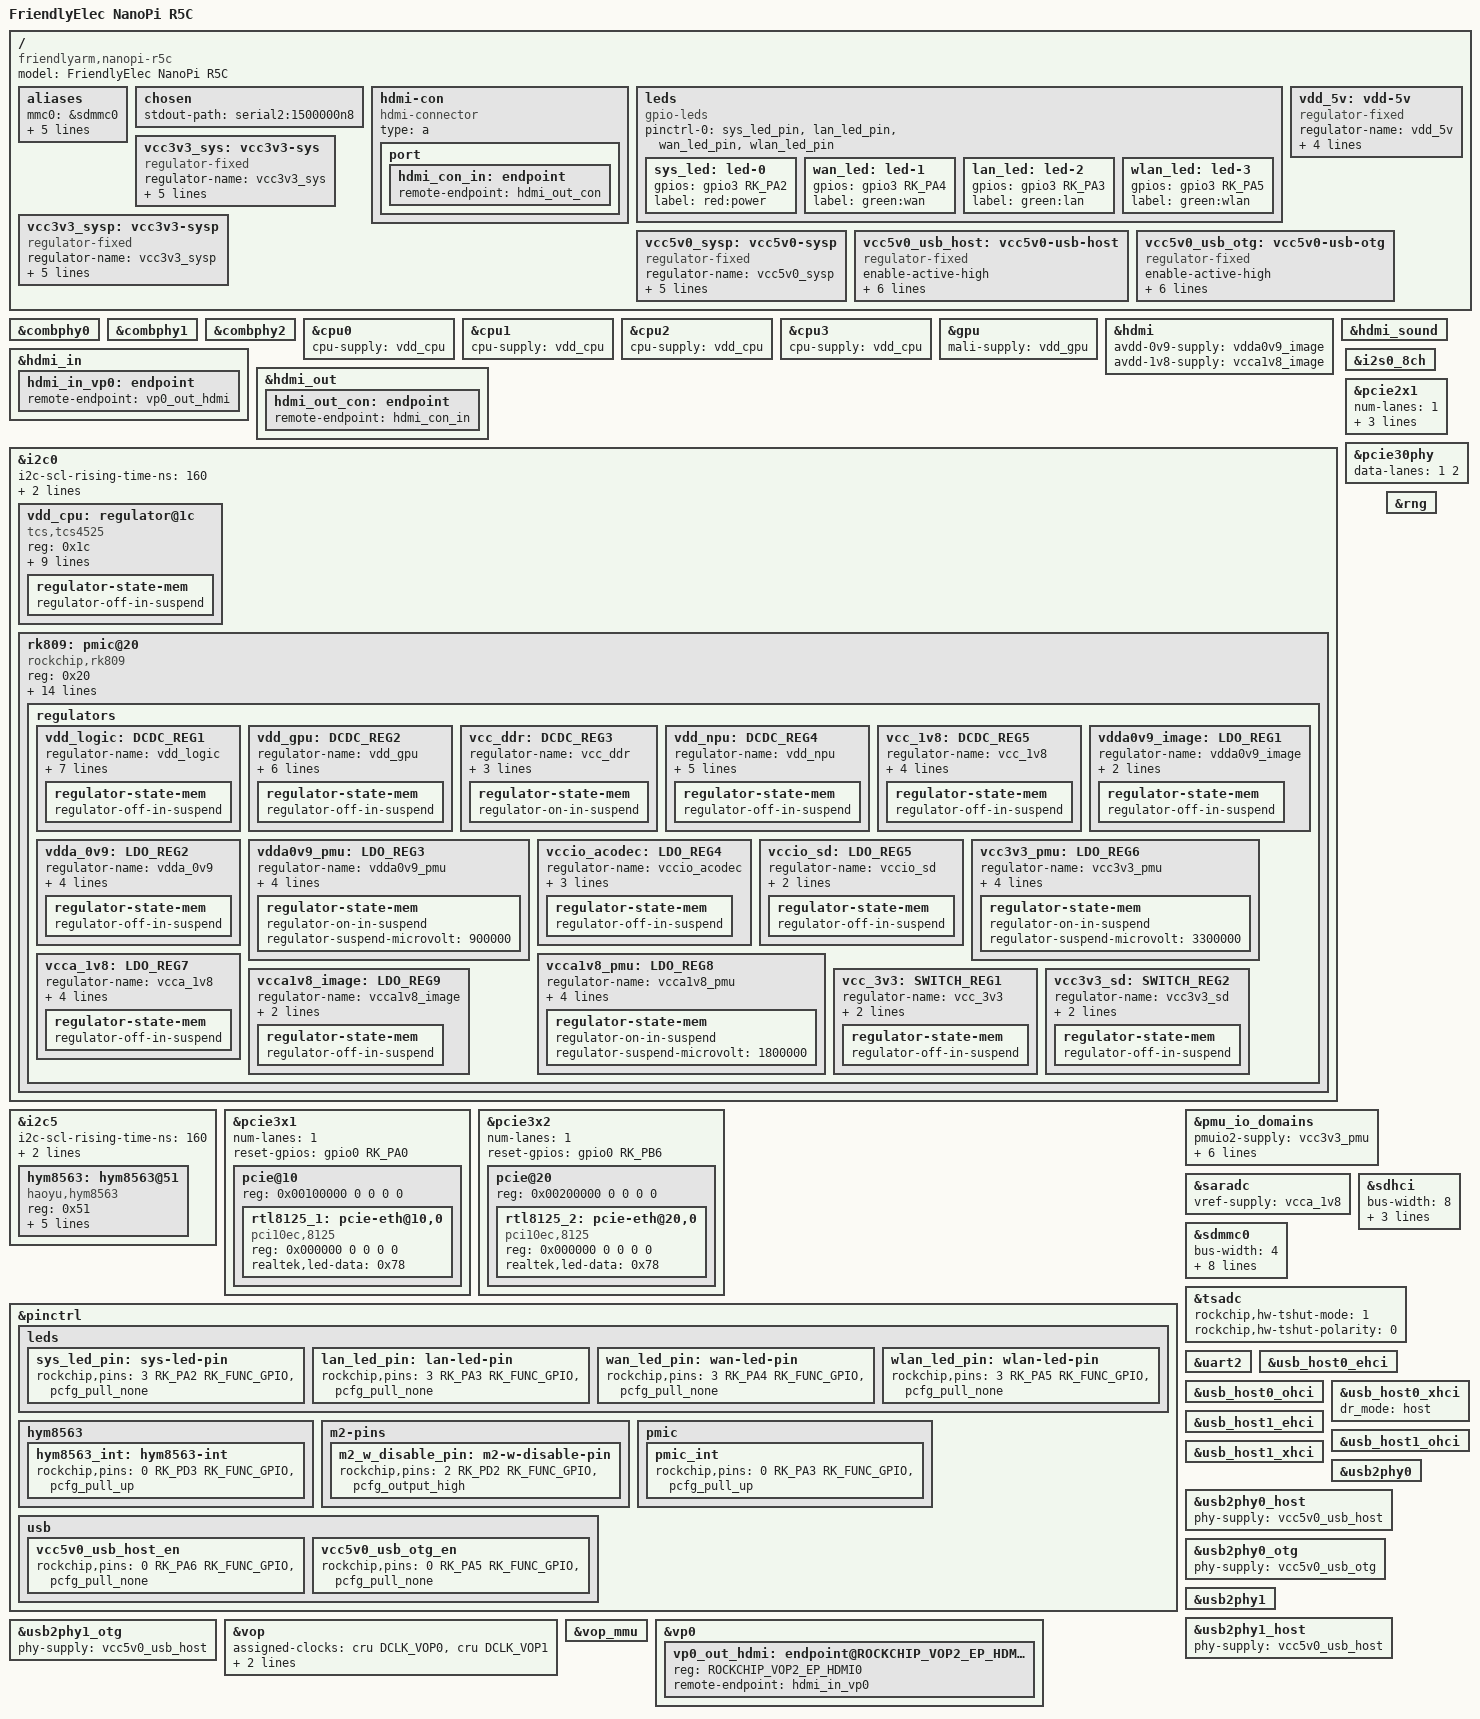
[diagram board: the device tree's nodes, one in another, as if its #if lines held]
// SPDX-License-Identifier: (GPL-2.0+ OR MIT)
/*
 * Copyright (c) 2021 FriendlyElec Computer Tech. Co., Ltd.
 * (http://www.friendlyarm.com)
 *
 */

/dts-v1/;

#include <dt-bindings/gpio/gpio.h>
#include <dt-bindings/leds/common.h>
#include <dt-bindings/pinctrl/rockchip.h>
#include <dt-bindings/soc/rockchip,vop2.h>
#include "rk3568.dtsi"

/ {
	model = "FriendlyElec NanoPi R5C";
	compatible = "friendlyarm,nanopi-r5c","rockchip,rk3568";

	aliases {
		mmc0 = &sdmmc0;
		mmc1 = &sdhci;

		led-boot = &sys_led;
		led-failsafe = &sys_led;
		led-running = &sys_led;
		led-upgrade = &sys_led;
	};

	chosen: chosen {
		stdout-path = "serial2:1500000n8";
	};

#ifdef DTS_NO_LEGACY
	hdmi-con {
		compatible = "hdmi-connector";
		type = "a";

		port {
			hdmi_con_in: endpoint {
				remote-endpoint = <&hdmi_out_con>;
			};
		};
	};
#endif

	leds {
		compatible = "gpio-leds";
		pinctrl-0 = <&sys_led_pin>, <&lan_led_pin>,
			    <&wan_led_pin>, <&wlan_led_pin>;
		pinctrl-names = "default";

		sys_led: led-0 {
			gpios = <&gpio3 RK_PA2 GPIO_ACTIVE_HIGH>;
			label = "red:power";
		};

		wan_led: led-1 {
			gpios = <&gpio3 RK_PA4 GPIO_ACTIVE_HIGH>;
			label = "green:wan";
		};

		lan_led: led-2 {
			gpios = <&gpio3 RK_PA3 GPIO_ACTIVE_HIGH>;
			label = "green:lan";
		};

		wlan_led: led-3 {
			gpios = <&gpio3 RK_PA5 GPIO_ACTIVE_HIGH>;
			label = "green:wlan";
		};
	};

	vdd_5v: vdd-5v {
		compatible = "regulator-fixed";
		regulator-name = "vdd_5v";
		regulator-always-on;
		regulator-boot-on;
		regulator-min-microvolt = <5000000>;
		regulator-max-microvolt = <5000000>;
	};

	vcc3v3_sys: vcc3v3-sys {
		compatible = "regulator-fixed";
		regulator-name = "vcc3v3_sys";
		regulator-always-on;
		regulator-boot-on;
		regulator-min-microvolt = <3300000>;
		regulator-max-microvolt = <3300000>;
		vin-supply = <&vdd_5v>;
	};

	vcc3v3_sysp: vcc3v3-sysp {
		compatible = "regulator-fixed";
		regulator-name = "vcc3v3_sysp";
		regulator-always-on;
		regulator-boot-on;
		regulator-min-microvolt = <3300000>;
		regulator-max-microvolt = <3300000>;
		vin-supply = <&vdd_5v>;
	};

	vcc5v0_sysp: vcc5v0-sysp {
		compatible = "regulator-fixed";
		regulator-name = "vcc5v0_sysp";
		regulator-always-on;
		regulator-boot-on;
		regulator-min-microvolt = <5000000>;
		regulator-max-microvolt = <5000000>;
		vin-supply = <&vcc3v3_sysp>;
	};

	vcc5v0_usb_host: vcc5v0-usb-host {
		compatible = "regulator-fixed";
		enable-active-high;
		gpio = <&gpio0 RK_PA6 GPIO_ACTIVE_HIGH>;
		pinctrl-names = "default";
		pinctrl-0 = <&vcc5v0_usb_host_en>;
		regulator-name = "vcc5v0_usb_host";
		regulator-min-microvolt = <5000000>;
		regulator-max-microvolt = <5000000>;
		vin-supply = <&vcc5v0_sysp>;
	};

	vcc5v0_usb_otg: vcc5v0-usb-otg {
		compatible = "regulator-fixed";
		enable-active-high;
		gpio = <&gpio0 RK_PA5 GPIO_ACTIVE_HIGH>;
		pinctrl-names = "default";
		pinctrl-0 = <&vcc5v0_usb_otg_en>;
		regulator-name = "vcc5v0_usb_otg";
		regulator-min-microvolt = <5000000>;
		regulator-max-microvolt = <5000000>;
		vin-supply = <&vcc5v0_sysp>;
	};
};

&combphy0 {
	status = "okay";
};

&combphy1 {
	status = "okay";
};

&combphy2 {
	status = "okay";
};

&cpu0 {
	cpu-supply = <&vdd_cpu>;
};

&cpu1 {
	cpu-supply = <&vdd_cpu>;
};

&cpu2 {
	cpu-supply = <&vdd_cpu>;
};

&cpu3 {
	cpu-supply = <&vdd_cpu>;
};

#ifdef DTS_NO_LEGACY
&gpu {
	mali-supply = <&vdd_gpu>;
	status = "okay";
};

&hdmi {
	avdd-0v9-supply = <&vdda0v9_image>;
	avdd-1v8-supply = <&vcca1v8_image>;
	status = "okay";
};

&hdmi_in {
	hdmi_in_vp0: endpoint {
		remote-endpoint = <&vp0_out_hdmi>;
	};
};

&hdmi_out {
	hdmi_out_con: endpoint {
		remote-endpoint = <&hdmi_con_in>;
	};
};

&hdmi_sound {
	status = "okay";
};
#endif

&i2c0 {
	i2c-scl-rising-time-ns = <160>;
	i2c-scl-falling-time-ns = <30>;
	clock-frequency = <400000>;
	status = "okay";

	vdd_cpu: regulator@1c {
		compatible = "tcs,tcs4525";
		reg = <0x1c>;
		fcs,suspend-voltage-selector = <1>;
		regulator-name = "vdd_cpu";
		regulator-always-on;
		regulator-boot-on;
		regulator-min-microvolt = <712500>;
		regulator-max-microvolt = <1390000>;
		regulator-init-microvolt = <900000>;
		regulator-ramp-delay = <2300>;
		vin-supply = <&vcc3v3_sys>;

		regulator-state-mem {
			regulator-off-in-suspend;
		};
	};

	rk809: pmic@20 {
		compatible = "rockchip,rk809";
		reg = <0x20>;
		interrupt-parent = <&gpio0>;
		interrupts = <RK_PA3 IRQ_TYPE_LEVEL_LOW>;
		#clock-cells = <1>;
		pinctrl-names = "default";
		pinctrl-0 = <&pmic_int>;
		rockchip,system-power-controller;
		wakeup-source;

		vcc1-supply = <&vcc3v3_sys>;
		vcc2-supply = <&vcc3v3_sys>;
		vcc3-supply = <&vcc3v3_sys>;
		vcc4-supply = <&vcc3v3_sys>;
		vcc5-supply = <&vcc3v3_sys>;
		vcc6-supply = <&vcc3v3_sys>;
		vcc7-supply = <&vcc3v3_sys>;
		vcc8-supply = <&vcc3v3_sys>;
		vcc9-supply = <&vcc3v3_sys>;

		regulators {
			vdd_logic: DCDC_REG1 {
				regulator-name = "vdd_logic";
				regulator-always-on;
				regulator-boot-on;
				regulator-init-microvolt = <900000>;
				regulator-initial-mode = <0x2>;
				regulator-min-microvolt = <500000>;
				regulator-max-microvolt = <1350000>;
				regulator-ramp-delay = <6001>;

				regulator-state-mem {
					regulator-off-in-suspend;
				};
			};

			vdd_gpu: DCDC_REG2 {
				regulator-name = "vdd_gpu";
				regulator-always-on;
				regulator-init-microvolt = <900000>;
				regulator-initial-mode = <0x2>;
				regulator-min-microvolt = <500000>;
				regulator-max-microvolt = <1350000>;
				regulator-ramp-delay = <6001>;

				regulator-state-mem {
					regulator-off-in-suspend;
				};
			};

			vcc_ddr: DCDC_REG3 {
				regulator-name = "vcc_ddr";
				regulator-always-on;
				regulator-boot-on;
				regulator-initial-mode = <0x2>;

				regulator-state-mem {
					regulator-on-in-suspend;
				};
			};

			vdd_npu: DCDC_REG4 {
				regulator-name = "vdd_npu";
				regulator-init-microvolt = <900000>;
				regulator-initial-mode = <0x2>;
				regulator-min-microvolt = <500000>;
				regulator-max-microvolt = <1350000>;
				regulator-ramp-delay = <6001>;

				regulator-state-mem {
					regulator-off-in-suspend;
				};
			};

			vcc_1v8: DCDC_REG5 {
				regulator-name = "vcc_1v8";
				regulator-always-on;
				regulator-boot-on;
				regulator-min-microvolt = <1800000>;
				regulator-max-microvolt = <1800000>;

				regulator-state-mem {
					regulator-off-in-suspend;
				};
			};

			vdda0v9_image: LDO_REG1 {
				regulator-name = "vdda0v9_image";
				regulator-min-microvolt = <900000>;
				regulator-max-microvolt = <900000>;

				regulator-state-mem {
					regulator-off-in-suspend;
				};
			};

			vdda_0v9: LDO_REG2 {
				regulator-name = "vdda_0v9";
				regulator-always-on;
				regulator-boot-on;
				regulator-min-microvolt = <900000>;
				regulator-max-microvolt = <900000>;

				regulator-state-mem {
					regulator-off-in-suspend;
				};
			};

			vdda0v9_pmu: LDO_REG3 {
				regulator-name = "vdda0v9_pmu";
				regulator-always-on;
				regulator-boot-on;
				regulator-min-microvolt = <900000>;
				regulator-max-microvolt = <900000>;

				regulator-state-mem {
					regulator-on-in-suspend;
					regulator-suspend-microvolt = <900000>;
				};
			};

			vccio_acodec: LDO_REG4 {
				regulator-name = "vccio_acodec";
				regulator-always-on;
				regulator-min-microvolt = <3300000>;
				regulator-max-microvolt = <3300000>;

				regulator-state-mem {
					regulator-off-in-suspend;
				};
			};

			vccio_sd: LDO_REG5 {
				regulator-name = "vccio_sd";
				regulator-min-microvolt = <1800000>;
				regulator-max-microvolt = <3300000>;

				regulator-state-mem {
					regulator-off-in-suspend;
				};
			};

			vcc3v3_pmu: LDO_REG6 {
				regulator-name = "vcc3v3_pmu";
				regulator-always-on;
				regulator-boot-on;
				regulator-min-microvolt = <3300000>;
				regulator-max-microvolt = <3300000>;

				regulator-state-mem {
					regulator-on-in-suspend;
					regulator-suspend-microvolt = <3300000>;
				};
			};

			vcca_1v8: LDO_REG7 {
				regulator-name = "vcca_1v8";
				regulator-always-on;
				regulator-boot-on;
				regulator-min-microvolt = <1800000>;
				regulator-max-microvolt = <1800000>;

				regulator-state-mem {
					regulator-off-in-suspend;
				};
			};

			vcca1v8_pmu: LDO_REG8 {
				regulator-name = "vcca1v8_pmu";
				regulator-always-on;
				regulator-boot-on;
				regulator-min-microvolt = <1800000>;
				regulator-max-microvolt = <1800000>;

				regulator-state-mem {
					regulator-on-in-suspend;
					regulator-suspend-microvolt = <1800000>;
				};
			};

			vcca1v8_image: LDO_REG9 {
				regulator-name = "vcca1v8_image";
				regulator-min-microvolt = <1800000>;
				regulator-max-microvolt = <1800000>;

				regulator-state-mem {
					regulator-off-in-suspend;
				};
			};

			vcc_3v3: SWITCH_REG1 {
				regulator-name = "vcc_3v3";
				regulator-always-on;
				regulator-boot-on;

				regulator-state-mem {
					regulator-off-in-suspend;
				};
			};

			vcc3v3_sd: SWITCH_REG2 {
				regulator-name = "vcc3v3_sd";
				regulator-always-on;
				regulator-boot-on;

				regulator-state-mem {
					regulator-off-in-suspend;
				};
			};
		};
	};
};

&i2c5 {
	i2c-scl-rising-time-ns = <160>;
	i2c-scl-falling-time-ns = <30>;
	clock-frequency = <400000>;
	status = "okay";

	hym8563: hym8563@51 {
		compatible = "haoyu,hym8563";
		reg = <0x51>;
		interrupt-parent = <&gpio0>;
		interrupts = <RK_PD3 IRQ_TYPE_LEVEL_LOW>;
		#clock-cells = <0>;
		clock-frequency = <32768>;
		clock-output-names = "xin32k";
		pinctrl-names = "default";
		pinctrl-0 = <&hym8563_int>;
	};
};

#ifdef DTS_NO_LEGACY
&i2s0_8ch {
	status = "okay";
};
#endif

&pcie2x1 {
	num-lanes = <1>;
	num-viewport = <4>;
	pinctrl-names = "default";
	pinctrl-0 = <&m2_w_disable_pin>;
	reset-gpios = <&gpio3 RK_PC1 GPIO_ACTIVE_HIGH>;
	status = "okay";
};

&pcie30phy {
	data-lanes = <1 2>;
	status = "okay";
};

&pcie3x1 {
	num-lanes = <1>;
	reset-gpios = <&gpio0 RK_PA0 GPIO_ACTIVE_HIGH>;
	status = "okay";

	pcie@10 {
		reg = <0x00100000 0 0 0 0>;
		#address-cells = <3>;
		#size-cells = <2>;

		rtl8125_1: pcie-eth@10,0 {
			compatible = "pci10ec,8125";
			reg = <0x000000 0 0 0 0>;

			realtek,led-data = <0x78>;
		};
	};
};

&pcie3x2 {
	num-lanes = <1>;
	reset-gpios = <&gpio0 RK_PB6 GPIO_ACTIVE_HIGH>;
	status = "okay";

	pcie@20 {
		reg = <0x00200000 0 0 0 0>;
		#address-cells = <3>;
		#size-cells = <2>;

		rtl8125_2: pcie-eth@20,0 {
			compatible = "pci10ec,8125";
			reg = <0x000000 0 0 0 0>;

			realtek,led-data = <0x78>;
		};
	};
};

&pinctrl {
	leds {
		sys_led_pin: sys-led-pin {
			rockchip,pins = <3 RK_PA2 RK_FUNC_GPIO &pcfg_pull_none>;
		};

		lan_led_pin: lan-led-pin {
			rockchip,pins = <3 RK_PA3 RK_FUNC_GPIO &pcfg_pull_none>;
		};

		wan_led_pin: wan-led-pin {
			rockchip,pins = <3 RK_PA4 RK_FUNC_GPIO &pcfg_pull_none>;
		};

		wlan_led_pin: wlan-led-pin {
			rockchip,pins = <3 RK_PA5 RK_FUNC_GPIO &pcfg_pull_none>;
		};
	};

	hym8563 {
		hym8563_int: hym8563-int {
			rockchip,pins = <0 RK_PD3 RK_FUNC_GPIO &pcfg_pull_up>;
		};
	};

	m2-pins {
		m2_w_disable_pin: m2-w-disable-pin {
			rockchip,pins = <2 RK_PD2 RK_FUNC_GPIO &pcfg_output_high>;
		};
	};

	pmic {
		pmic_int: pmic_int {
			rockchip,pins = <0 RK_PA3 RK_FUNC_GPIO &pcfg_pull_up>;
		};
	};

	usb {
		vcc5v0_usb_host_en: vcc5v0_usb_host_en {
			rockchip,pins = <0 RK_PA6 RK_FUNC_GPIO &pcfg_pull_none>;
		};
		vcc5v0_usb_otg_en: vcc5v0_usb_otg_en {
			rockchip,pins = <0 RK_PA5 RK_FUNC_GPIO &pcfg_pull_none>;
		};
	};
};

&pmu_io_domains {
	pmuio2-supply = <&vcc3v3_pmu>;
	vccio1-supply = <&vccio_acodec>;
	vccio3-supply = <&vccio_sd>;
	vccio4-supply = <&vcc_1v8>;
	vccio5-supply = <&vcc_3v3>;
	vccio6-supply = <&vcc_1v8>;
	vccio7-supply = <&vcc_3v3>;
	status = "okay";
};

&rng {
	status = "okay";
};

&saradc {
	vref-supply = <&vcca_1v8>;
	status = "okay";
};

&sdhci {
	bus-width = <8>;
	max-frequency = <200000000>;
	non-removable;
	pinctrl-names = "default";
	pinctrl-0 = <&emmc_bus8 &emmc_clk &emmc_cmd>;
	status = "okay";
};

&sdmmc0 {
	bus-width = <4>;
	cap-sd-highspeed;
	cd-gpios = <&gpio0 RK_PA4 GPIO_ACTIVE_LOW>;
	disable-wp;
	pinctrl-names = "default";
	pinctrl-0 = <&sdmmc0_bus4 &sdmmc0_clk &sdmmc0_cmd &sdmmc0_det>;
	sd-uhs-sdr104;
	vmmc-supply = <&vcc3v3_sd>;
	vqmmc-supply = <&vccio_sd>;
	status = "okay";
};

&tsadc {
	rockchip,hw-tshut-mode = <1>;
	rockchip,hw-tshut-polarity = <0>;
	status = "okay";
};

&uart2 {
	status = "okay";
};

&usb_host0_ehci {
	status = "okay";
};

&usb_host0_ohci {
	status = "okay";
};

&usb_host0_xhci {
	dr_mode = "host";
	status = "okay";
};

&usb_host1_ehci {
	status = "okay";
};

&usb_host1_ohci {
	status = "okay";
};

&usb_host1_xhci {
	status = "okay";
};

&usb2phy0 {
	status = "okay";
};

&usb2phy0_host {
	phy-supply = <&vcc5v0_usb_host>;
	status = "okay";
};

&usb2phy0_otg {
	phy-supply = <&vcc5v0_usb_otg>;
	status = "okay";
};

&usb2phy1 {
	status = "okay";
};

&usb2phy1_host {
	phy-supply = <&vcc5v0_usb_host>;
	status = "okay";
};

&usb2phy1_otg {
	phy-supply = <&vcc5v0_usb_host>;
	status = "okay";
};

#ifdef DTS_NO_LEGACY
&vop {
	assigned-clocks = <&cru DCLK_VOP0>, <&cru DCLK_VOP1>;
	assigned-clock-parents = <&pmucru PLL_HPLL>, <&cru PLL_VPLL>;
	status = "okay";
};

&vop_mmu {
	status = "okay";
};

&vp0 {
	vp0_out_hdmi: endpoint@ROCKCHIP_VOP2_EP_HDMI0 {
		reg = <ROCKCHIP_VOP2_EP_HDMI0>;
		remote-endpoint = <&hdmi_in_vp0>;
	};
};
#endif
